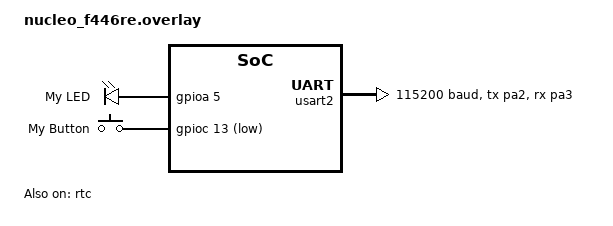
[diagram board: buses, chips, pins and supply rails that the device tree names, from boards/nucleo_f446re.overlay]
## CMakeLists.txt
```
#-------------------------------------------------------------------------------
# STM32 Zephyr RTOS Data Logger 
#-------------------------------------------------------------------------------

cmake_minimum_required(VERSION 3.20.0)

find_package(Zephyr REQUIRED HINTS $ENV{ZEPHYR_BASE})

project(014_STM32_Dummy_Temp_Sensor)

# Add source files
target_sources(app PRIVATE src/main.c
                            src/temperature_sensor.c
                            src/rtc.c
                            src/sensor_task.c
                            src/logger_task.c
                            src/workqueue_handler.c
                            src/app_init.c)

# Add include directory
target_include_directories(app PRIVATE ${CMAKE_CURRENT_SOURCE_DIR}/include)
```

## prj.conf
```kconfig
# Copyright (c) 2021 Nordic Semiconductor ASA
# SPDX-License-Identifier: Apache-2.0
#
# This file contains selected Kconfig options for the application.

CONFIG_GPIO=y
CONFIG_RTC=y

CONFIG_PRINTK=y
CONFIG_CONSOLE=y
CONFIG_SERIAL=y
CONFIG_LOG=y
CONFIG_UART_CONSOLE=y

CONFIG_STDOUT_CONSOLE=y
CONFIG_NEWLIB_LIBC=y
CONFIG_NEWLIB_LIBC_FLOAT_PRINTF=y
CONFIG_CBPRINTF_FP_SUPPORT=y
```

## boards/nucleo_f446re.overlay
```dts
/ {

    chosen {
        zephyr,console = &usart2;
        zephyr,shell-uart = &usart2;
    };

    leds {
        compatible = "gpio-leds";

        my_led: led_0 {
            gpios = <&gpioa 5 GPIO_ACTIVE_HIGH>;
            label = "My LED";
        };
    };

    buttons {
        compatible = "gpio-keys";

        my_button: button_0 {
            gpios = <&gpioc 13 (GPIO_PULL_UP | GPIO_ACTIVE_LOW)>;
            label = "My Button";
        };
    };

    aliases {
        led0 = &my_led;
        sw0 = &my_button;
        uart0 = &usart2;
    };
};

&usart2 {
        pinctrl-0 = <&usart2_tx_pa2 &usart2_rx_pa3>;
        pinctrl-names = "default";
        current-speed = <115200>;
        status = "okay";
};

/* Enable RTC */
&rtc {
    status = "okay";
};
```

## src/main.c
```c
/***********************************************************
Project Name : STM32 Zephyr RTOS Data Logger 
Author 		 : Sunil Sutar
Date   		 : 21-05-2026

Description  : This project demonstrates real-time sensor acquisition, 
			   inter-thread communication, synchronization, and 
			   modular firmware architecture.
*********************************************************** */

#include "common.h"
#include "temperature_sensor.h"
#include "rtc.h"
#include "sensor_task.h"
#include "logger_task.h"
#include "app_init.h"

/*----------------------------------------------------------
 * main function
 *---------------------------------------------------------*/

int main()
{
	printk("STM32 Zephyr RTOS Data Logger\n");

	/* temperature sensor init */
	temp_sensor_init();

	/* rtc init */
	if(rtc_init_function() != 0) {
		printk("RTC Init Failed\n");
		return 0;
	}

	/* start timer */
	start_timer();

	while(1)
	{
		k_sleep(K_SECONDS(1));
	}

	return 0;
}
```

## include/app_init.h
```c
#ifndef APP_INIT_H
#define APP_INIT_H

void start_timer(void);

#endif
```

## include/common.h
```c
#ifndef COMMON_H
#define COMMON_H

#include <zephyr/kernel.h>
#include <zephyr/device.h>
#include <zephyr/sys/printk.h>
#include <zephyr/drivers/rtc.h>
#include <zephyr/logging/log.h>

#define STACK_SIZE             2048
#define THREAD_PRIORITY        5

#define LOG_BUFFER_SIZE        50

/* timer period */
#define SENSOR_PERIOD_MS        1000

/*----------------------------------------------------------
 * Sensor Data Structure
 *---------------------------------------------------------*/
struct sensor_data
{
    float temperature;
    struct rtc_time timestamp;
};

extern struct k_sem sensor_sem;
extern struct k_msgq sensor_msgq;
extern struct k_mutex buffer_mutex;

extern struct sensor_data log_buffer[LOG_BUFFER_SIZE];
extern uint32_t log_index;

#endif
```

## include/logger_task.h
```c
#ifndef LOGGER_TASK_H
#define LOGGER_TASK_H

void logger_thread(void);

#endif
```

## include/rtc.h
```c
#ifndef RTC_H
#define RTC_H

#include <zephyr/drivers/rtc.h>

int rtc_init_function(void);

void rtc_get_current_time(struct rtc_time *time);

#endif
```

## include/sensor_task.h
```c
#ifndef SENSOR_TASK_H
#define SENSOR_TASK_H

void sensor_thread(void);

#endif
```

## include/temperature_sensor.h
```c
#ifndef TEMPERATURE_SENSOR_H_
#define TEMPERATURE_SENSOR_H_

int temp_sensor_init(void);

float temp_sensor_read(void);

#endif
```

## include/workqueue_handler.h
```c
#ifndef WORKQUEUE_HANDLER_H
#define WORKQUEUE_HANDLER_H

void submit_log_work(void);

#endif
```

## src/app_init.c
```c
#include "common.h"

/*----------------------------------------------------------
 * Semaphore
 *---------------------------------------------------------*/

K_SEM_DEFINE(sensor_sem, 0, 1);

/*----------------------------------------------------------
 * Mutex
 *---------------------------------------------------------*/

K_MUTEX_DEFINE(buffer_mutex);

/*----------------------------------------------------------
 * Message Queue
 *---------------------------------------------------------*/

K_MSGQ_DEFINE(sensor_msgq, sizeof(struct sensor_data), 10, 4);

/*----------------------------------------------------------
 * Timer Callback
 *---------------------------------------------------------*/

void timer_handler(struct k_timer *timer)
{
    ARG_UNUSED(timer);

    k_sem_give(&sensor_sem);
}

/*----------------------------------------------------------
 * Software Timer
 *---------------------------------------------------------*/

K_TIMER_DEFINE(sensor_timer, timer_handler, NULL);

/*----------------------------------------------------------
 * Start Software Timer
 *---------------------------------------------------------*/

void start_timer(void)
{
    k_timer_start(&sensor_timer, K_MSEC(SENSOR_PERIOD_MS), K_MSEC(SENSOR_PERIOD_MS));
}
```

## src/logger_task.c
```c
#include "common.h"
#include "logger_task.h"
#include "workqueue_handler.h"

struct sensor_data log_buffer[LOG_BUFFER_SIZE];

uint32_t log_index = 0;

/*----------------------------------------------------------
 * Logger Thread
 *---------------------------------------------------------*/

void logger_thread(void)
{
    struct sensor_data rx_data;\

    while(1)
    {
        /* Get the data from message queue */
        k_msgq_get(&sensor_msgq, &rx_data, K_FOREVER);

        /* Mutex Lock */
        k_mutex_lock(&buffer_mutex, K_FOREVER);

        log_buffer[log_index++] = rx_data;

        if(log_index >= LOG_BUFFER_SIZE)
        {
            log_index = 0;
        }

        /* Mutex Unlock */
        k_mutex_unlock(&buffer_mutex);

        printk("[%02d:%02d:%02d] Temp = %.2f C\n",
                rx_data.timestamp.tm_hour,
                rx_data.timestamp.tm_min,
                rx_data.timestamp.tm_sec,
                (double) rx_data.temperature);

        submit_log_work();
    }
}

/*----------------------------------------------------------
 * Thread Definition
 *---------------------------------------------------------*/

/* Creating logger thread */
K_THREAD_DEFINE(logger_thread_id,
                STACK_SIZE,
                logger_thread,
                NULL,
                NULL,
                NULL,
                THREAD_PRIORITY,
                0,
                0);
```

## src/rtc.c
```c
#include "rtc.h"

const struct device *rtc_dev = DEVICE_DT_GET(DT_NODELABEL(rtc));

/*----------------------------------------------------------
 * RTC Init
 *---------------------------------------------------------*/

int rtc_init_function(void)
{
    int ret;

    /* Check rtc device */
	if(! device_is_ready(rtc_dev)){
		printk("rtc is not ready\r\n");
		return 0;
	}

    //set time
	struct rtc_time time = {
		.tm_sec = 00,
		.tm_min = 00,
		.tm_hour = 11,
		.tm_mday = 20,
		.tm_mon = 5,
		.tm_year = 2026-1900,
		.tm_wday = 3,
	};

	ret = rtc_set_time(rtc_dev, &time);

	if(ret < 0) {
		printk("Failed to Set RTC Time: %d\n", ret);
		return 0;
	}

    printk("RTC Time Set\n");

    return 0;
}

/*----------------------------------------------------------
 * RTC Get Current Time
 *---------------------------------------------------------*/

void rtc_get_current_time(struct rtc_time *time)
{
    rtc_get_time(rtc_dev, time);
}
```

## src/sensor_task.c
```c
#include "common.h"
#include "temperature_sensor.h"
#include "rtc.h"
#include "sensor_task.h"

/*----------------------------------------------------------
 * Sensor Thread
 *---------------------------------------------------------*/

void sensor_thread(void)
{
    struct sensor_data data;

    while(1)
    {
        /* Take the Semaphore */
        k_sem_take(&sensor_sem, K_FOREVER);

        /* Get Data : temperature */
        data.temperature = temp_sensor_read();

        /* Get Data : rtc time */
        rtc_get_current_time(&data.timestamp);

        /* Put the data into message queue */
        k_msgq_put(&sensor_msgq, &data, K_NO_WAIT);
    }
}

/*----------------------------------------------------------
 * Thread Definition
 *---------------------------------------------------------*/

K_THREAD_DEFINE(sensor_thread_id,
                STACK_SIZE,
                sensor_thread,
                NULL,
                NULL,
                NULL,
                THREAD_PRIORITY,
                0,
                0);
```

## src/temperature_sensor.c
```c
#include <zephyr/kernel.h>
#include <zephyr/sys/printk.h>

#include "temperature_sensor.h"

static float dummy_temperature = 30.0f;

/*----------------------------------------------------------
 * Dummy Temperature Sensor Init
 *---------------------------------------------------------*/

int temp_sensor_init(void)
{
    printk("Dummy Temperature sensor initialized\n");

    return 0;
}

/*----------------------------------------------------------
 * Dummy Temperature Sensor Read
 *---------------------------------------------------------*/

float temp_sensor_read(void)
{
    dummy_temperature += 0.5f;

     if (dummy_temperature > 40.0f) {
        dummy_temperature = 30.0f;
    }

    return dummy_temperature;
} 
```
